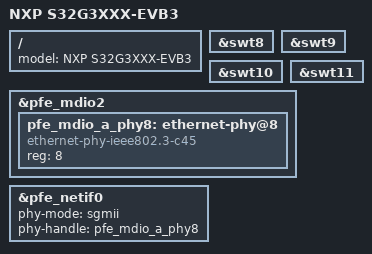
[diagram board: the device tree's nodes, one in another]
// SPDX-License-Identifier: GPL-2.0-or-later
/*
 * Copyright 2022 NXP
 */

/dts-v1/;
#include "fsl-s32g3.dtsi"
#include "fsl-s32gxxxa-evb.dtsi"
/ {
	model = "NXP S32G3XXX-EVB3";
};

&swt8 {
	status = "okay";
};

&swt9 {
	status = "okay";
};

&swt10 {
	status = "okay";
};

&swt11 {
	status = "okay";
};

&pfe_mdio2 {
	/* AQR113 on S32G-PROCEVB3-S */
	pfe_mdio_a_phy8: ethernet-phy@8 {
		compatible = "ethernet-phy-ieee802.3-c45";
		reg = <8>;
	};
};

&pfe_netif0 {
	phy-mode = "sgmii";
	phy-handle = <&pfe_mdio_a_phy8>;
};
